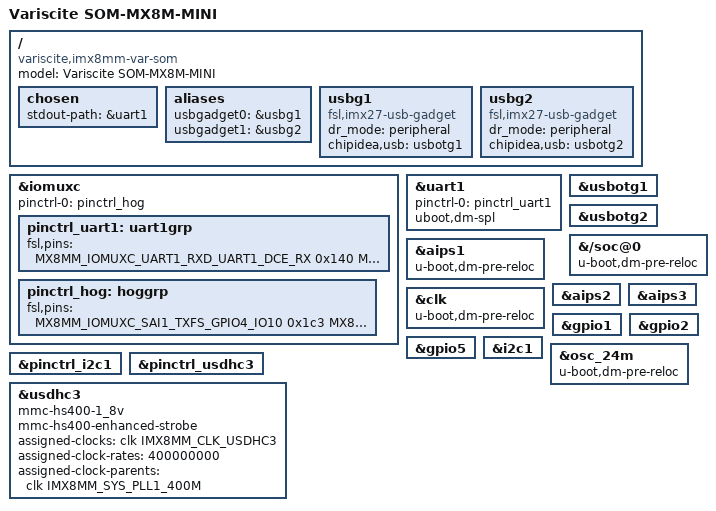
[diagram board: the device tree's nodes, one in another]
/*
 * Copyright 2018 NXP
 * Copyright 2018-2020 Variscite Ltd.
 *
 * This program is free software; you can redistribute it and/or
 * modify it under the terms of the GNU General Public License
 * as published by the Free Software Foundation; either version 2
 * of the License, or (at your option) any later version.
 *
 * This program is distributed in the hope that it will be useful,
 * but WITHOUT ANY WARRANTY; without even the implied warranty of
 * MERCHANTABILITY or FITNESS FOR A PARTICULAR PURPOSE.  See the
 * GNU General Public License for more details.
 */

/dts-v1/;

#include "imx8mm-var-som.dtsi"

/ {
	model = "Variscite SOM-MX8M-MINI";
	compatible = "variscite,imx8mm-var-som", "fsl,imx8mm";

	chosen {
		stdout-path = &uart1;
	};

	aliases {
		usbgadget0 = &usbg1;
		usbgadget1 = &usbg2;
	};

    /*
	firmware {
		optee {
			compatible = "linaro,optee-tz";
			method = "smc";
		};
	};
    */

	usbg1: usbg1 {
		compatible = "fsl,imx27-usb-gadget";
		dr_mode = "peripheral";
		chipidea,usb = <&usbotg1>;
		status = "okay";
	};

	usbg2: usbg2 {
		compatible = "fsl,imx27-usb-gadget";
		dr_mode = "peripheral";
		chipidea,usb = <&usbotg2>;
		status = "okay";
	};

};

&iomuxc {
	u-boot,dm-spl;
    pinctrl-names = "default";
    pinctrl-0 = <&pinctrl_hog>;

	pinctrl_uart1: uart1grp {
		fsl,pins = <
			MX8MM_IOMUXC_UART1_RXD_UART1_DCE_RX		0x140
			MX8MM_IOMUXC_UART1_TXD_UART1_DCE_TX		0x140
		>;
		u-boot,dm-spl;
	};

	pinctrl_hog: hoggrp {
		fsl,pins = <
			MX8MM_IOMUXC_SAI1_TXFS_GPIO4_IO10		0x1c3
			MX8MM_IOMUXC_GPIO1_IO15_GPIO1_IO15		0x1c3
			MX8MM_IOMUXC_SAI3_TXD_GPIO5_IO1			0x1c3
			MX8MM_IOMUXC_GPIO1_IO06_GPIO1_IO6		0x1c3
			MX8MM_IOMUXC_SAI2_TXD0_GPIO4_IO26		0x1c3
			MX8MM_IOMUXC_GPIO1_IO07_GPIO1_IO7		0x1c3
			MX8MM_IOMUXC_ECSPI1_MISO_GPIO5_IO8		0x1c3
			MX8MM_IOMUXC_SAI5_MCLK_GPIO3_IO25		0x1c3
			MX8MM_IOMUXC_SAI2_TXFS_GPIO4_IO24		0x1c3
			MX8MM_IOMUXC_SD2_CLK_GPIO2_IO13			0x1c3
		>;
		u-boot,dm-spl;
	};

/*
	pinctrl_lvds_to_hdmi: lvdshdmigrp {
		fsl,pins = <
			MX8MM_IOMUXC_SAI1_TXFS_GPIO4_IO10		0x1c3
			MX8MM_IOMUXC_GPIO1_IO15_GPIO1_IO15		0x1c3
		>;
		u-boot,dm-spl;
	};

	pinctrl_slave_mcu: slavemcugrp {
		fsl,pins = <
			MX8MM_IOMUXC_SAI2_TXD0_GPIO4_IO26		0x1c3
			MX8MM_IOMUXC_GPIO1_IO07_GPIO1_IO7		0x1c3
		>;
		u-boot,dm-spl;
	};

	pinctrl_generic_gpio: generic_gpio_grp {
		fsl,pins = <
			MX8MM_IOMUXC_ECSPI1_MISO_GPIO5_IO8		0x1c3
		>;
		u-boot,dm-spl;
	};

	pinctrl_power_button: power_buttongrp {
		fsl,pins = <
			MX8MM_IOMUXC_SAI5_MCLK_GPIO3_IO25		0x1c3
		>;
		u-boot,dm-spl;
	};

	pinctrl_mp: mpgrp {
		fsl,pins = <
			MX8MM_IOMUXC_SAI2_TXFS_GPIO4_IO24		0x1c3
			MX8MM_IOMUXC_SD2_CLK_GPIO2_IO13			0x1c3
		>;
		u-boot,dm-spl;
	};
    */

};

&uart1 { /* console */
	pinctrl-names = "default";
	pinctrl-0 = <&pinctrl_uart1>;
	uboot,dm-spl;
	status = "okay";
};

&usbotg1 {
	status = "okay";
};

&usbotg2 {
	status = "okay";
};

&{/soc@0} {
	u-boot,dm-pre-reloc;
	u-boot,dm-spl;
};

&aips1 {
	u-boot,dm-spl;
	u-boot,dm-pre-reloc;
};

&aips2 {
	u-boot,dm-spl;
};

&aips3 {
	u-boot,dm-spl;
};

&clk {
	u-boot,dm-spl;
	u-boot,dm-pre-reloc;
	/delete-property/ assigned-clocks;
	/delete-property/ assigned-clock-parents;
	/delete-property/ assigned-clock-rates;
};

&gpio1 {
	u-boot,dm-spl;
};

&gpio2 {
	u-boot,dm-spl;
};

&gpio5 {
	u-boot,dm-spl;
};

&i2c1 {
	u-boot,dm-spl;
};

&osc_24m {
	u-boot,dm-spl;
	u-boot,dm-pre-reloc;
};

&pinctrl_i2c1 {
	u-boot,dm-spl;
};

&pinctrl_usdhc3 {
	u-boot,dm-spl;
};

&usdhc3 {
	u-boot,dm-spl;
	mmc-hs400-1_8v;
	mmc-hs400-enhanced-strobe;
	assigned-clocks = <&clk IMX8MM_CLK_USDHC3>;
	assigned-clock-rates = <400000000>;
	assigned-clock-parents = <&clk IMX8MM_SYS_PLL1_400M>;
};
